VERSION ""

NS_ :

BS_:

BU_:

BO_ 592 HEARTBEAT: 8 Vector__XXX
 SG_ State : 0|8@1+ (1,0) [0|0] "" Vector__XXX
 SG_ Counter : 8|8@1+ (1,0) [0|0] "" Vector__XXX

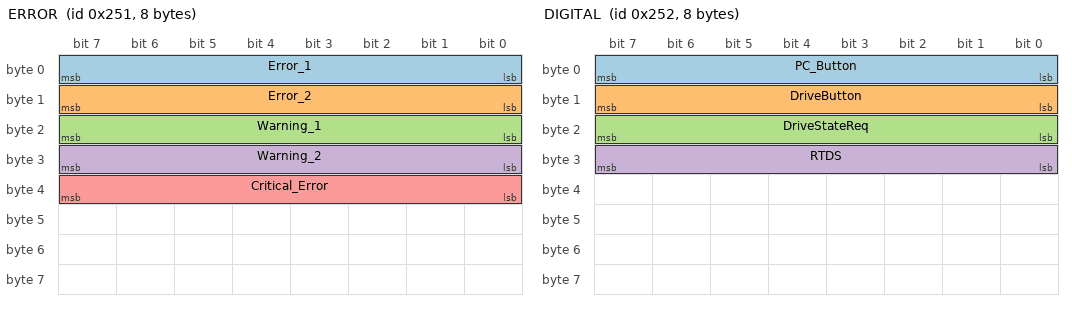
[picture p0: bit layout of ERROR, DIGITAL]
BO_ 593 ERROR: 8 Vector__XXX
 SG_ Error_1 : 0|8@1+ (1,0) [0|0] "" Vector__XXX
 SG_ Error_2 : 8|8@1+ (1,0) [0|0] "" Vector__XXX
 SG_ Warning_1 : 16|8@1+ (1,0) [0|0] "" Vector__XXX
 SG_ Warning_2 : 24|8@1+ (1,0) [0|0] "" Vector__XXX
 SG_ Critical_Error : 32|8@1+ (1,0) [0|0] "" Vector__XXX

BO_ 594 DIGITAL: 8 Vector__XXX
 SG_ PC_Button : 0|8@1+ (1,0) [0|0] "" Vector__XXX
 SG_ DriveButton : 8|8@1+ (1,0) [0|0] "" Vector__XXX
 SG_ DriveStateReq : 16|8@1+ (1,0) [0|0] "" Vector__XXX
 SG_ RTDS : 24|8@1+ (1,0) [0|0] "" Vector__XXX

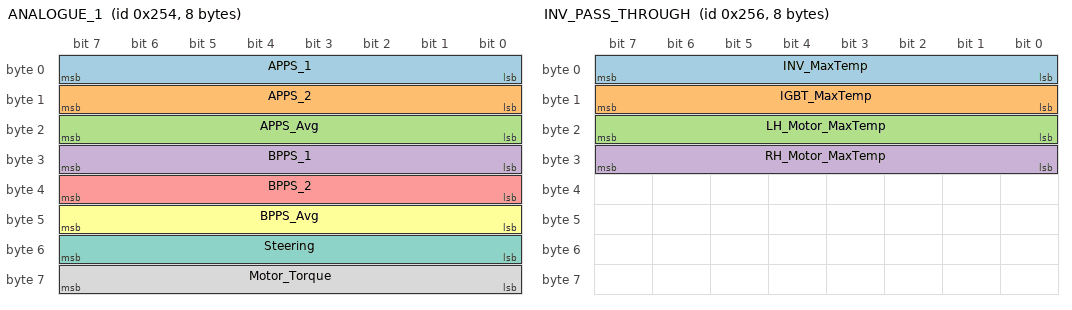
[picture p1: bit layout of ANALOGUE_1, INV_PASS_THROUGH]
BO_ 596 ANALOGUE_1: 8 Vector__XXX
 SG_ APPS_1 : 0|8@1+ (1,0) [0|0] "" Vector__XXX
 SG_ APPS_2 : 8|8@1+ (1,0) [0|0] "" Vector__XXX
 SG_ APPS_Avg : 16|8@1+ (1,0) [0|0] "" Vector__XXX
 SG_ BPPS_1 : 24|8@1+ (1,0) [0|0] "" Vector__XXX
 SG_ BPPS_2 : 32|8@1+ (1,0) [0|0] "" Vector__XXX
 SG_ BPPS_Avg : 40|8@1+ (1,0) [0|0] "" Vector__XXX
 SG_ Steering : 48|8@1+ (1,0) [0|0] "" Vector__XXX
 SG_ Motor_Torque : 56|8@1+ (1,0) [0|0] "" Vector__XXX

BO_ 598 INV_PASS_THROUGH: 8 Vector__XXX
 SG_ INV_MaxTemp : 0|8@1+ (1,0) [0|0] "" Vector__XXX
 SG_ IGBT_MaxTemp : 8|8@1+ (1,0) [0|0] "" Vector__XXX
 SG_ LH_Motor_MaxTemp : 16|8@1+ (1,0) [0|0] "" Vector__XXX
 SG_ RH_Motor_MaxTemp : 24|8@1+ (1,0) [0|0] "" Vector__XXX

BO_ 531 INV1_SET_POINT: 8 Vector__XXX

BO_ 547 INV2_SET_POINT: 8 Vector__XXX

BO_ 563 INV3_SET_POINT: 8 Vector__XXX

BO_ 579 INV4_SET_POINT: 8 Vector__XXX

BO_ 597 ANALOGUE_2: 8 Vector__XXX
 SG_ LV_Voltage : 7|16@0+ (0.1,0) [0|0] "" Vector__XXX
